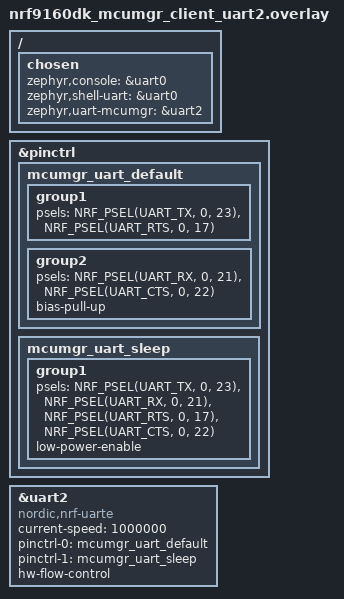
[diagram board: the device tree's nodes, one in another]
/*
 * Copyright (c) 2023 Nordic Semiconductor ASA
 *
 * SPDX-License-Identifier: LicenseRef-Nordic-5-Clause
 */

/* Generic PIN definition for UART2 or UART1 to nRF52840  */
&pinctrl {
	mcumgr_uart_default: mcumgr_uart_default {
		group1 {
			psels = <NRF_PSEL(UART_TX, 0, 23)>,
				<NRF_PSEL(UART_RTS, 0, 17)>;
			};
		group2 {
			psels = <NRF_PSEL(UART_RX, 0, 21)>,
				<NRF_PSEL(UART_CTS, 0, 22)>;
				bias-pull-up;
		};
	};

	mcumgr_uart_sleep: mcumgr_uart_sleep {
		group1 {
			psels = <NRF_PSEL(UART_TX, 0, 23)>,
				<NRF_PSEL(UART_RX, 0, 21)>,
				<NRF_PSEL(UART_RTS, 0, 17)>,
				<NRF_PSEL(UART_CTS, 0, 22)>;
				low-power-enable;
		};
	};
};

&uart2 {
	compatible = "nordic,nrf-uarte";
	current-speed = <1000000>;
	status = "okay";
	pinctrl-0 = <&mcumgr_uart_default>;
	pinctrl-1 = <&mcumgr_uart_sleep>;
	pinctrl-names = "default", "sleep";
	hw-flow-control;
};

/ {
	chosen {
		zephyr,console = &uart0;
		zephyr,shell-uart = &uart0;
		zephyr,uart-mcumgr = &uart2;
	};
};
